# HT32F12365_66 register map
File version: 1.1
CPU: CM3 r2p0, little endian, no MPU, no FPU, 4 interrupt priority bits
Registers are 32-bit, read-write, reset 0x0 unless marked. A register's access mark holds for its fields unless they carry their own. Offsets are from the block's base; [hi:lo] are bit positions; {n}, {i} and the like mark numbered series; 'fields as' and 'values as' point back to an identical list.

## CMP
Base 0x40058000
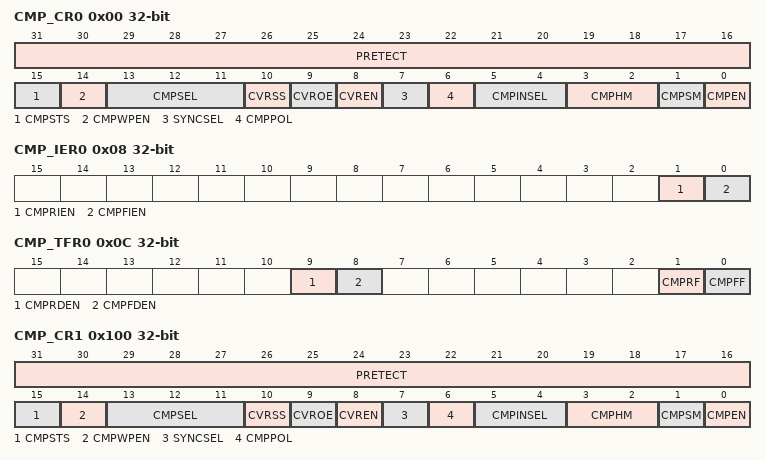
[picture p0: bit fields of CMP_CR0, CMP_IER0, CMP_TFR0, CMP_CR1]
0x00 CMP_CR0
  [31:16] PRETECT
  [15] CMPSTS
  [14] CMPWPEN
  [13:11] CMPSEL — CMPOSEL
  [10] CVRSS
  [9] CVROE
  [8] CVREN
  [7] SYNCSEL
  [6] CMPPOL
  [5:4] CMPINSEL
  [3:2] CMPHM
  [1] CMPSM
  [0] CMPEN
0x04 CMP_VALR0
  [5:0] CVRVAL
0x08 CMP_IER0
  [1] CMPRIEN, [0] CMPFIEN
0x0C CMP_TFR0
  [9] CMPRDEN, [8] CMPFDEN, [1] CMPRF, [0] CMPFF
0x100 CMP_CR1
  fields as CMP_CR0
0x104 CMP_VALR1
  [5:0] CVRVAL
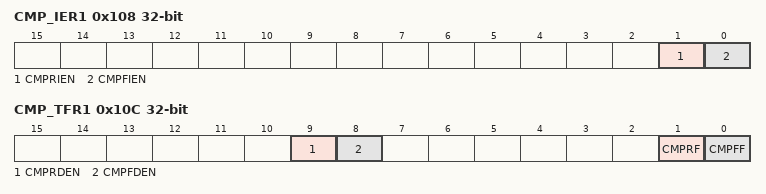
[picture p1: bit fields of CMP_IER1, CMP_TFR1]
0x108 CMP_IER1
  [1] CMPRIEN, [0] CMPFIEN
0x10C CMP_TFR1
  [9] CMPRDEN — CMPRF
  [8] CMPFDEN
  [1] CMPRF
  [0] CMPFF

## MCTM0
Base 0x4002C000
Same registers: MCTM1 0x4002D000
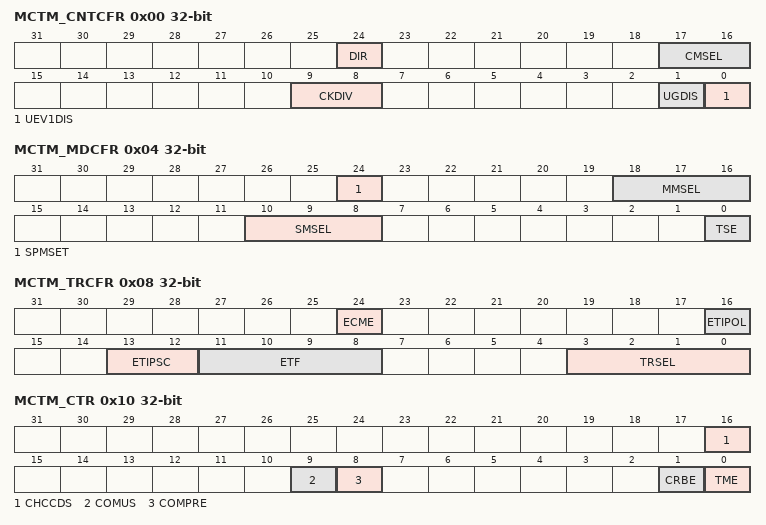
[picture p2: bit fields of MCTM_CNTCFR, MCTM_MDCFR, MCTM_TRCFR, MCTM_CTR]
0x00 MCTM_CNTCFR
  [24] DIR, [17:16] CMSEL, [9:8] CKDIV, [1] UGDIS, [0] UEV1DIS
0x04 MCTM_MDCFR
  [24] SPMSET, [18:16] MMSEL, [10:8] SMSEL, [0] TSE
0x08 MCTM_TRCFR
  [24] ECME, [16] ETIPOL, [13:12] ETIPSC, [11:8] ETF, [3:0] TRSEL
0x10 MCTM_CTR
  [16] CHCCDS, [9] COMUS, [8] COMPRE, [1] CRBE, [0] TME
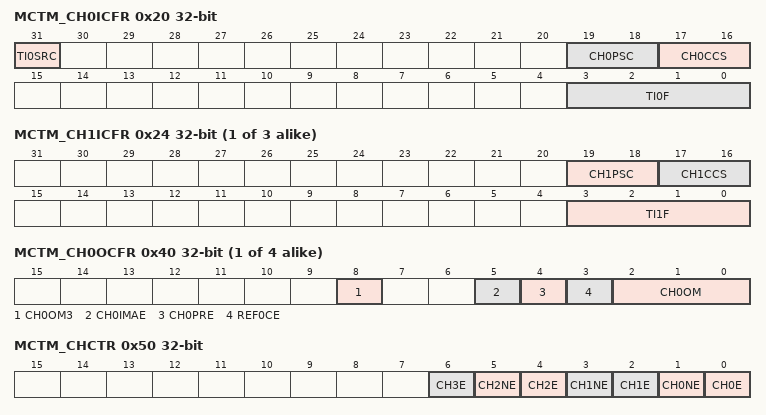
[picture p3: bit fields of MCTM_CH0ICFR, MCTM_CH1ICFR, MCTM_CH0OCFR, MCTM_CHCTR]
0x20 MCTM_CH0ICFR
  [31] TI0SRC, [19:18] CH0PSC, [17:16] CH0CCS, [3:0] TI0F
{0x20+4i} MCTM_CH{i}ICFR (i=1..3)
  [19:18] CH{i}PSC, [17:16] CH{i}CCS, [3:0] TI{i}F
{0x40+4i} MCTM_CH{i}OCFR (i=0..3)
  [8] CH{i}OM3, [5] CH{i}IMAE, [4] CH{i}PRE, [3] REF{i}CE, [2:0] CH{i}OM
0x50 MCTM_CHCTR
  [2n] CH{n}E (n=0..3), [5] CH2NE, [3] CH1NE, [1] CH0NE
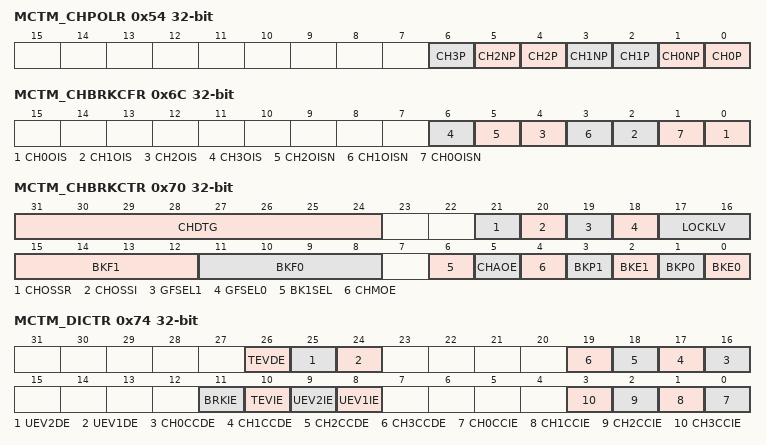
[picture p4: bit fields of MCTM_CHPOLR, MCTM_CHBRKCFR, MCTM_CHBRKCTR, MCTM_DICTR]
0x54 MCTM_CHPOLR
  [2n] CH{n}P (n=0..3), [5] CH2NP, [3] CH1NP, [1] CH0NP
0x6C MCTM_CHBRKCFR
  [2n] CH{n}OIS (n=0..3), [5] CH2OISN, [3] CH1OISN, [1] CH0OISN
0x70 MCTM_CHBRKCTR
  [31:24] CHDTG, [21] CHOSSR, [20] CHOSSI, [19] GFSEL1, [18] GFSEL0, [17:16] LOCKLV, [15:12] BKF1, [11:8] BKF0, [6] BK1SEL, [5] CHAOE, [4] CHMOE, [3] BKP1, [2] BKE1, [1] BKP0, [0] BKE0
0x74 MCTM_DICTR
  [26] TEVDE, [25] UEV2DE, [24] UEV1DE, [n+16] CH{n}CCDE (n=0..3), [11] BRKIE, [10] TEVIE, [9] UEV2IE, [8] UEV1IE, [n] CH{n}CCIE (n=0..3)
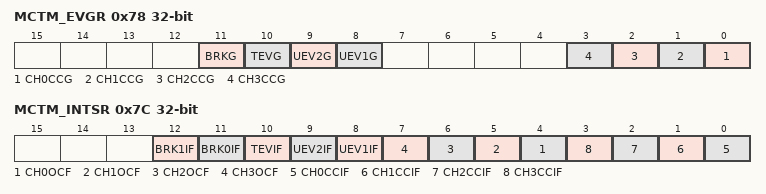
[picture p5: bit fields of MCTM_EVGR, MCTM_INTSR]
0x78 MCTM_EVGR
  [11] BRKG, [10] TEVG, [9] UEV2G, [8] UEV1G, [n] CH{n}CCG (n=0..3)
0x7C MCTM_INTSR
  [12] BRK1IF, [11] BRK0IF, [10] TEVIF, [9] UEV2IF, [8] UEV1IF, [n+4] CH{n}OCF (n=0..3), [n] CH{n}CCIF (n=0..3)
0x80 MCTM_CNTR
  [15:0] CNTV
0x84 MCTM_PSCR
  [15:0] PSCV
0x88 MCTM_CRR
  [15:0] CRV
0x8C MCTM_REPR
  [7:0] REPV
{0x90+4i} MCTM_CH{i}CCR (i=0..3)
  [15:0] CH{i}CCV
{0xA0+4i} MCTM_CH{i}ACR (i=0..3)
  [15:0] CH{i}ACV

## GPTM0
Base 0x4006E000
Same registers: GPTM1 0x4006F000
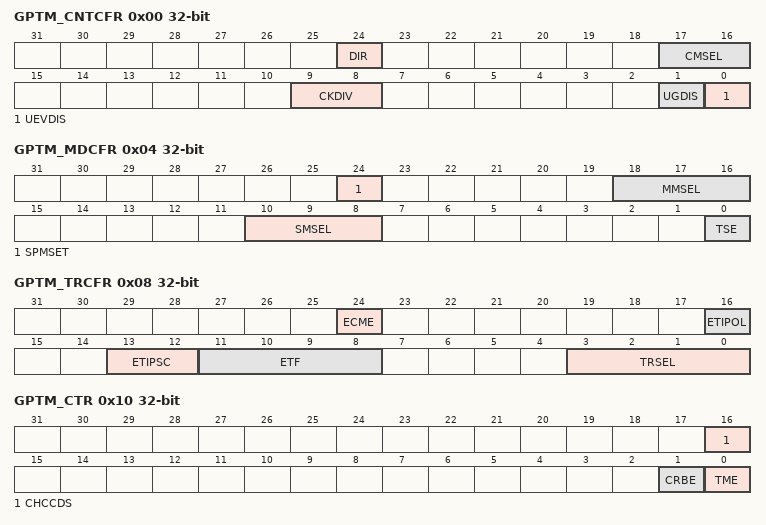
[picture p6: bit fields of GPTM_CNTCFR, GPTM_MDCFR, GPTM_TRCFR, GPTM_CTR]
0x00 GPTM_CNTCFR
  [24] DIR, [17:16] CMSEL, [9:8] CKDIV, [1] UGDIS, [0] UEVDIS
0x04 GPTM_MDCFR
  [24] SPMSET, [18:16] MMSEL, [10:8] SMSEL, [0] TSE
0x08 GPTM_TRCFR
  [24] ECME, [16] ETIPOL, [13:12] ETIPSC, [11:8] ETF, [3:0] TRSEL
0x10 GPTM_CTR
  [16] CHCCDS, [1] CRBE, [0] TME
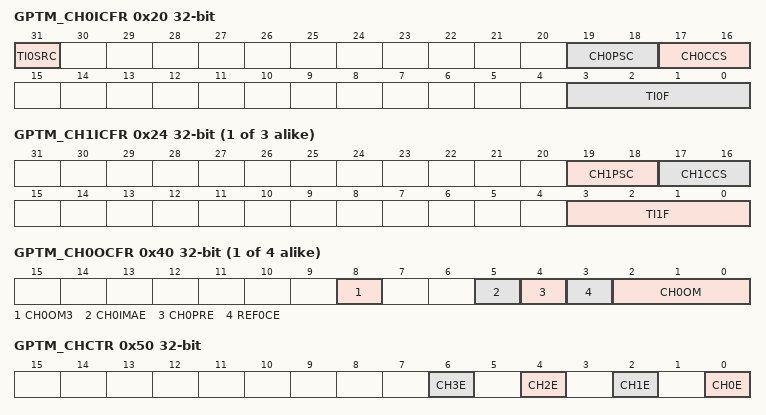
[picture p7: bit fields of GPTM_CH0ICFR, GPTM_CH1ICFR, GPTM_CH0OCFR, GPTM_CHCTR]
0x20 GPTM_CH0ICFR
  [31] TI0SRC, [19:18] CH0PSC, [17:16] CH0CCS, [3:0] TI0F
{0x20+4i} GPTM_CH{i}ICFR (i=1..3)
  [19:18] CH{i}PSC, [17:16] CH{i}CCS, [3:0] TI{i}F
{0x40+4i} GPTM_CH{i}OCFR (i=0..3)
  [8] CH{i}OM3, [5] CH{i}IMAE, [4] CH{i}PRE, [3] REF{i}CE, [2:0] CH{i}OM
0x50 GPTM_CHCTR
  [2n] CH{n}E (n=0..3)
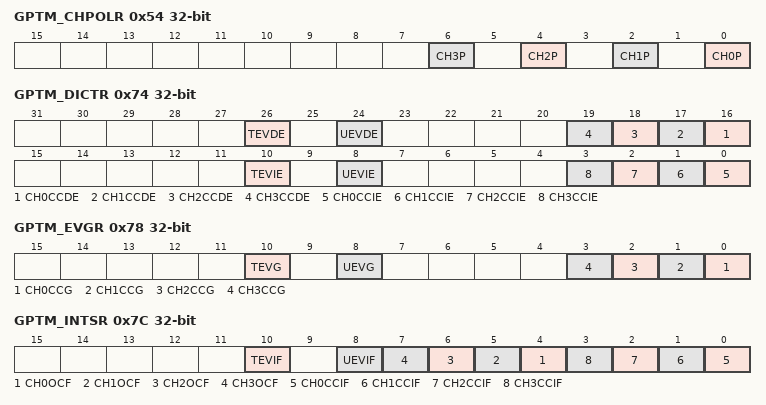
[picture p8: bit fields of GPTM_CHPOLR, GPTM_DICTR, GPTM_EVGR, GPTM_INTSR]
0x54 GPTM_CHPOLR
  [2n] CH{n}P (n=0..3)
0x74 GPTM_DICTR
  [26] TEVDE, [24] UEVDE, [n+16] CH{n}CCDE (n=0..3), [10] TEVIE, [8] UEVIE, [n] CH{n}CCIE (n=0..3)
0x78 GPTM_EVGR
  [10] TEVG, [8] UEVG, [n] CH{n}CCG (n=0..3)
0x7C GPTM_INTSR
  [10] TEVIF, [8] UEVIF, [n+4] CH{n}OCF (n=0..3), [n] CH{n}CCIF (n=0..3)
0x80 GPTM_CNTR
  [15:0] CNTV
0x84 GPTM_PSCR
  [15:0] PSCV
0x88 GPTM_CRR
  [15:0] CRV
{0x90+4i} GPTM_CH{i}CCR (i=0..3)
  [15:0] CH{i}CCV
{0xA0+4i} GPTM_CH{i}ACR (i=0..3)
  [15:0] CH{i}ACV

## BFTM0
Base 0x40076000
Same registers: BFTM1 0x40077000
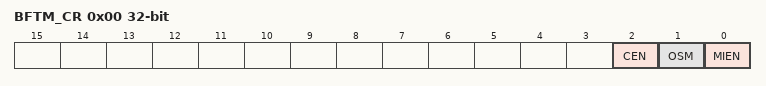
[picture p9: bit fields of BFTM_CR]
0x00 BFTM_CR
  [2] CEN, [1] OSM, [0] MIEN
0x04 BFTM_SR
  [0] MIF
0x08 BFTM_CNTR
0x0C BFTM_CMPR
  [31:0] CMP

## RTC
Base 0x4006A000
0x00 RTC_CNT
  [31:0] RTCCNT
0x04 RTC_CMP
  [31:0] RTCCMP
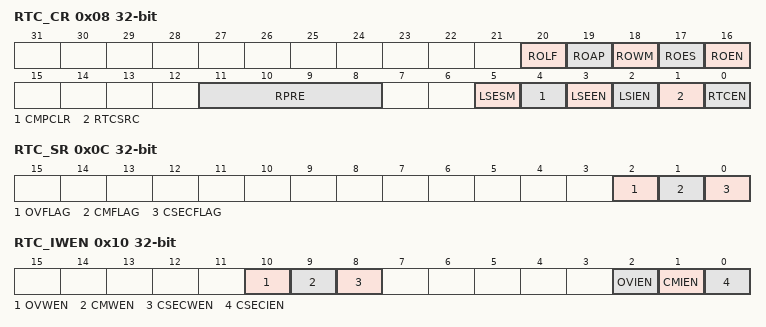
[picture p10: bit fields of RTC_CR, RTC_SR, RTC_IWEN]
0x08 RTC_CR
  [20] ROLF, [19] ROAP, [18] ROWM, [17] ROES, [16] ROEN, [11:8] RPRE, [5] LSESM, [4] CMPCLR, [3] LSEEN, [2] LSIEN, [1] RTCSRC, [0] RTCEN
0x0C RTC_SR
  [2] OVFLAG, [1] CMFLAG, [0] CSECFLAG
0x10 RTC_IWEN
  [10] OVWEN, [9] CMWEN, [8] CSECWEN, [2] OVIEN, [1] CMIEN, [0] CSECIEN

## Notices in the file
Copyright (C) 2010 ARM Limited. All rights reserved.
ARM Limited (ARM) is supplying this SVD description for use with Cortex-M3
processor based microcontrollers.  This file and or content can be freely
distributed within development tools that are supporting such ARM based
processors.
THIS SOFTWARE IS PROVIDED "AS IS".  NO WARRANTIES, WHETHER EXPRESS, IMPLIED
OR STATUTORY, INCLUDING, BUT NOT LIMITED TO, IMPLIED WARRANTIES OF
MERCHANTABILITY AND FITNESS FOR A PARTICULAR PURPOSE APPLY TO THIS SOFTWARE.
ARM SHALL NOT, IN ANY CIRCUMSTANCES, BE LIABLE FOR SPECIAL, INCIDENTAL, OR
CONSEQUENTIAL DAMAGES, FOR ANY REASON WHATSOEVER.
